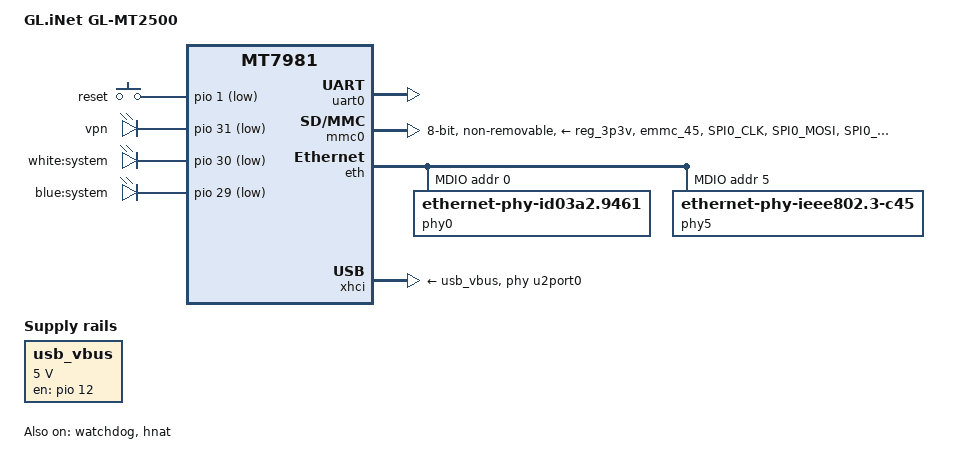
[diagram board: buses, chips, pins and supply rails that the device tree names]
/dts-v1/;
#include "mt7981.dtsi"
#include <dt-bindings/input/input.h>

/ {
	model = "GL.iNet GL-MT2500";
	compatible = "glinet,gl-mt2500","mediatek,mt7981";

	aliases {
		serial0 = &uart0;
		label-mac-device = &gmac0;
		led-boot = &led_white;
		led-failsafe = &led_white;
		led-running = &led_blue;
		led-upgrade = &led_blue;
	};

	chosen {
		bootargs = "console=ttyS0,115200n1 loglevel=8  \
				earlycon=uart8250,mmio32,0x11002000 \
				root=PARTLABEL=rootfs rootwait rootfstype=squashfs,f2fs \
				block2mtd.block2mtd=/dev/mmcblk0p1,65536,log";
	};

	gpio-keys {
		compatible = "gpio-keys";

		reset {
			label = "reset";
			linux,code = <KEY_RESTART>;
			gpios = <&pio 1 GPIO_ACTIVE_LOW>;
		};
	};

	leds {
		compatible = "gpio-leds";

		led_vpn: led@0 {
			label = "vpn";
			gpios = <&pio 31 GPIO_ACTIVE_LOW>;
		};

		led_white: led@1 {
			label = "white:system";
			gpios = <&pio 30 GPIO_ACTIVE_LOW>;
		};

		led_blue: led@2 {
			label = "blue:system";
			gpios = <&pio 29 GPIO_ACTIVE_LOW>;
			default-state = "on";
		};
	};

	usb_vbus: regulator-usb-vbus {
		compatible = "regulator-fixed";
		regulator-name = "usb_vbus";
		regulator-min-microvolt = <5000000>;
		regulator-max-microvolt = <5000000>;
		gpios = <&pio 12 GPIO_ACTIVE_HIGH>;
		enable-active-high;
		regulator-boot-on;
	};
};

&uart0 {
	status = "okay";
};

&watchdog {
	status = "okay";
};

&mmc0 {
	pinctrl-names = "default", "state_uhs";
	pinctrl-0 = <&mmc0_pins_default>;
	pinctrl-1 = <&mmc0_pins_uhs>;
	bus-width = <8>;
	max-frequency = <26000000>;
	cap-mmc-highspeed;
	vmmc-supply = <&reg_3p3v>;
	non-removable;
	status = "okay";
};

&eth {
	status = "okay";

	gmac0: mac@0 {
		compatible = "mediatek,eth-mac";
		reg = <0>;
		phy-mode = "2500base-x";
		phy-handle = <&phy5>;
	};

	gmac1: mac@1 {
		compatible = "mediatek,eth-mac";
		reg = <1>;
		phy-mode = "gmii";
		phy-handle = <&phy0>;
	};

	mdio: mdio-bus {
		#address-cells = <1>;
		#size-cells = <0>;

		reset-gpios = <&pio 14 GPIO_ACTIVE_LOW>;
		reset-delay-us = <100000>;
		reset-post-delay-us = <100000>;

		phy0: ethernet-phy@0 {
			compatible = "ethernet-phy-id03a2.9461";
			reg = <0>;
			phy-mode = "gmii";
			nvmem-cells = <&phy_calibration>;
			nvmem-cell-names = "phy-cal-data";
		};

		phy5: phy@5 {
			compatible = "ethernet-phy-ieee802.3-c45";
			reg = <5>;
		};
	};
};

&hnat {
	mtketh-wan = "eth0";
	mtketh-lan = "eth1";
	mtketh-ppd = "eth1";
	mtketh-max-gmac = <2>;
	mtketh-ppe-num = <2>;
	status = "okay";
};

&pio {

	spic_pins: spi1-pins {
		mux {
			function = "spi";
			groups = "spi1_1";
		};
	};

	mmc0_pins_default: mmc0-pins-default {
		mux {
			function = "flash";
			groups = "emmc_45";
		};
		conf-cmd-dat {
			pins = "SPI0_CLK", "SPI0_MOSI", "SPI0_MISO",
			       "SPI0_CS", "SPI0_HOLD", "SPI0_WP",
			       "SPI1_CLK", "SPI1_MOSI", "SPI1_MISO";
			input-enable;
			drive-strength = <MTK_DRIVE_12mA>;
			mediatek,pull-up-adv = <1>;	/* pull-up 10K */
		};
		conf-clk {
			pins = "SPI1_CS";
			drive-strength = <MTK_DRIVE_12mA>;
			mediatek,pull-down-adv = <2>;	/* pull-down 50K */
		};
	};

	mmc0_pins_uhs: mmc0-pins-uhs {
		mux {
			function = "flash";
			groups = "emmc_45";
		};
		conf-cmd-dat {
			pins = "SPI0_CLK", "SPI0_MOSI", "SPI0_MISO",
			       "SPI0_CS", "SPI0_HOLD", "SPI0_WP",
			       "SPI1_CLK", "SPI1_MOSI", "SPI1_MISO";
			input-enable;
			drive-strength = <MTK_DRIVE_12mA>;
			mediatek,pull-up-adv = <1>;	/* pull-up 10K */
		};

		conf-clk {
			pins = "SPI1_CS";
			drive-strength = <MTK_DRIVE_12mA>;
			mediatek,pull-down-adv = <2>;	/* pull-down 50K */
		};
	};
};

&xhci {
	mediatek,u3p-dis-msk = <0x0>;
	phys = <&u2port0 PHY_TYPE_USB2>,
	       <&u3port0 PHY_TYPE_USB3>;
	vusb33-supply = <&reg_3p3v>;
	vbus-supply = <&usb_vbus>;
	status = "okay";
};
